VERSION ""

NS_ :

BS_:

BU_: TIS_SN2000

BO_ 2630877422 TIS_SN2000_CMD: 8 Vector__XXX
 SG_ SN2000_Set_MetaData_Time m1114112 : 32|32@1+ (1,0) [0|0] "ms"  TIS_SN2000
 SG_ SN2000_Set_Averages m1048576 : 32|16@1+ (1,0) [1|65535] ""  TIS_SN2000
 SG_ SN2000_Send_IDs m917504 : 24|8@1+ (1,0) [0|0] ""  TIS_SN2000
 SG_ SN2000_Sweep_Stepsize m851968 : 32|32@1- (1,0) [0|0] ""  TIS_SN2000
 SG_ SN2000_Sweep_Stop m786432 : 32|32@1- (1,0) [10000|1000000] ""  TIS_SN2000
 SG_ SN2000_Sweep_Start m720896 : 32|32@1- (1,0) [10000|1000000] ""  TIS_SN2000
 SG_ SN2000_Factory_Reset m589824 : 24|8@1+ (1,0) [0|0] ""  TIS_SN2000
 SG_ SN2000_Set_Gain_F3 m524802 : 32|16@1+ (1,0) [0|2047] ""  TIS_SN2000
 SG_ SN2000_Set_Gain_F2 m524546 : 32|16@1+ (1,0) [0|2047] ""  TIS_SN2000
 SG_ SN2000_Set_Gain_F1 m524290 : 32|16@1+ (1,0) [0|2047] ""  TIS_SN2000
 SG_ SN2000_Set_AdditionalData_Time m393216 : 32|32@1+ (1,0) [0|0] "ms"  TIS_SN2000
 SG_ SN2000_Set_Sample_Time m327680 : 32|32@1+ (1,0) [0|0] "ms"  TIS_SN2000
 SG_ SN2000_Set_Baud m262144 : 24|8@1+ (1,0) [0|5] ""  TIS_SN2000
 SG_ SN2000_Set_F3 m131584 : 32|32@1- (1,0) [10000|1000000] "Hz"  TIS_SN2000
 SG_ SN2000_Set_F2 m131328 : 32|32@1- (1,0) [10000|1000000] "Hz"  TIS_SN2000
 SG_ SN2000_Set_F1 m131072 : 32|32@1- (1,0) [10000|1000000] "Hz"  TIS_SN2000
 SG_ SN2000_Save_Settings m65536 : 24|8@1+ (1,0) [0|0] ""  TIS_SN2000
 SG_ SN2000_Go_Idle m0 : 24|8@1+ (1,0) [0|0] ""  TIS_SN2000
 SG_ SN2000_CMD M : 0|24@1+ (1,0) [0|0] ""  TIS_SN2000

BO_ 2630887150 TIS_SN2000_ERef_Sweep_Amp: 8 TIS_SN2000
 SG_ SN2000_ERef_Sweep_Amp_F : 0|32@1- (1,0) [0|1000000000] "Hz" Vector__XXX
 SG_ SN2000_ERef_Sweep_Amp : 32|32@1- (1,0) [-65535|65535] "" Vector__XXX

BO_ 2630887406 TIS_SN2000_ERef_Sweep_Ph: 8 TIS_SN2000
 SG_ SN2000_ERef_Sweep_Ph_F : 0|32@1- (1,0) [0|1000000000] "Hz" Vector__XXX
 SG_ SN2000_ERef_Sweep_Ph : 32|32@1- (57.295779513,0) [-65535|65535] "" Vector__XXX

BO_ 2630887662 TIS_SN2000_EMicro_Sweep_Amp: 8 TIS_SN2000
 SG_ SN2000_EMicro_Sweep_Amp_F : 0|32@1- (1,0) [0|1000000000] "Hz" Vector__XXX
 SG_ SN2000_EMicro_Sweep_Amp : 32|32@1- (1,0) [-65535|65535] "" Vector__XXX

BO_ 2630887918 TIS_SN2000_EMicro_Sweep_Ph: 8 TIS_SN2000
 SG_ SN2000_EMicro_Sweep_Ph_F : 0|32@1- (1,0) [0|1000000000] "Hz" Vector__XXX
 SG_ SN2000_EMicro_Sweep_Ph : 32|32@1- (57.295779513,0) [-65535|65535] "" Vector__XXX

BO_ 2630888174 TIS_SN2000_E1_Sweep_Amp: 8 TIS_SN2000
 SG_ SN2000_E1_Sweep_Amp_F : 0|32@1- (1,0) [0|1000000000] "Hz" Vector__XXX
 SG_ SN2000_E1_Sweep_Amp : 32|32@1- (1,0) [-65535|65535] "" Vector__XXX

BO_ 2630888430 TIS_SN2000_E1_Sweep_Ph: 8 TIS_SN2000
 SG_ SN2000_E1_Sweep_Ph_F : 0|32@1- (1,0) [0|1000000000] "Hz" Vector__XXX
 SG_ SN2000_E1_Sweep_Ph : 32|32@1- (57.295779513,0) [-65535|65535] "" Vector__XXX

BO_ 2630888686 TIS_SN2000_E2_Sweep_Amp: 8 TIS_SN2000
 SG_ SN2000_E2_Sweep_Amp_F : 0|32@1- (1,0) [0|1000000000] "Hz" Vector__XXX
 SG_ SN2000_E2_Sweep_Amp : 32|32@1- (1,0) [-65535|65535] "" Vector__XXX

BO_ 2630888942 TIS_SN2000_E2_Sweep_Ph: 8 TIS_SN2000
 SG_ SN2000_E2_Sweep_Ph_F : 0|32@1- (1,0) [0|1000000000] "Hz" Vector__XXX
 SG_ SN2000_E2_Sweep_Ph : 32|32@1- (57.295779513,0) [-65535|65535] "" Vector__XXX

BO_ 2630889198 TIS_SN2000_E3_Sweep_Amp: 8 TIS_SN2000
 SG_ SN2000_E3_Sweep_Amp_F : 0|32@1- (1,0) [0|1000000000] "Hz" Vector__XXX
 SG_ SN2000_E3_Sweep_Amp : 32|32@1- (1,0) [-65535|65535] "" Vector__XXX

BO_ 2630889454 TIS_SN2000_E3_Sweep_Ph: 8 TIS_SN2000
 SG_ SN2000_E3_Sweep_Ph_F : 0|32@1- (1,0) [0|1000000000] "Hz" Vector__XXX
 SG_ SN2000_E3_Sweep_Ph : 32|32@1- (57.295779513,0) [-65535|65535] "" Vector__XXX

BO_ 2630889710 TIS_SN2000_EA_Sweep_Amp: 8 TIS_SN2000
 SG_ SN2000_EA_Sweep_Amp_F : 0|32@1- (1,0) [0|1000000000] "Hz" Vector__XXX
 SG_ SN2000_EA_Sweep_Amp : 32|32@1- (1,0) [-65535|65535] "" Vector__XXX

BO_ 2630889966 TIS_SN2000_EA_Sweep_Ph: 8 TIS_SN2000
 SG_ SN2000_EA_Sweep_Ph_F : 0|32@1- (1,0) [0|1000000000] "Hz" Vector__XXX
 SG_ SN2000_EA_Sweep_Ph : 32|32@1- (57.295779513,0) [-65535|65535] "" Vector__XXX

BO_ 2630877678 TIS_SN2000_ID: 4 TIS_SN2000
 SG_ SN2000_ID : 0|16@1+ (1,0) [0|65535] "" Vector__XXX

BO_ 2630877934 TIS_SN2000_Error: 1 TIS_SN2000
 SG_ SN2000_Error : 0|8@1+ (1,0) [0|255] "" Vector__XXX

BO_ 2630878190 TIS_SN2000_UID_Low: 8 TIS_SN2000
 SG_ SN2000_UID_Low : 0|64@1+ (1,0) [0|0] "" Vector__XXX

BO_ 2630878446 TIS_SN2000_UID_High: 4 TIS_SN2000
 SG_ SN2000_UID_High : 0|32@1+ (1,0) [0|0] "" Vector__XXX

BO_ 2630878702 TIS_SN2000_Temp_1_2: 8 TIS_SN2000
 SG_ SN2000_T1 : 0|32@1- (1,0) [-100|200] "C" Vector__XXX
 SG_ SN2000_T2 : 32|32@1- (1,0) [-100|200] "C" Vector__XXX

BO_ 2630878958 TIS_SN2000_Temp_3_4: 8 TIS_SN2000
 SG_ SN2000_T3 : 0|32@1- (1,0) [-100|200] "C" Vector__XXX
 SG_ SN2000_T4 : 32|32@1- (1,0) [-100|200] "C" Vector__XXX

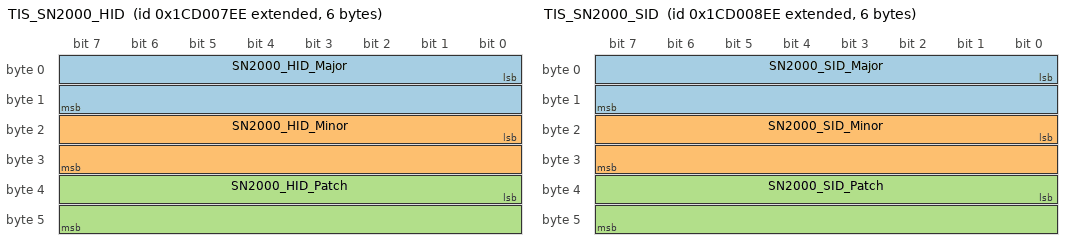
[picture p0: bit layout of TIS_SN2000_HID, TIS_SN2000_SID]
BO_ 2630879214 TIS_SN2000_HID: 6 TIS_SN2000
 SG_ SN2000_HID_Major : 0|16@1+ (1,0) [0|0] "" Vector__XXX
 SG_ SN2000_HID_Minor : 16|16@1+ (1,0) [0|0] "" Vector__XXX
 SG_ SN2000_HID_Patch : 32|16@1+ (1,0) [0|0] "" Vector__XXX

BO_ 2630879470 TIS_SN2000_SID: 6 TIS_SN2000
 SG_ SN2000_SID_Major : 0|16@1+ (1,0) [0|0] "" Vector__XXX
 SG_ SN2000_SID_Minor : 16|16@1+ (1,0) [0|0] "" Vector__XXX
 SG_ SN2000_SID_Patch : 32|16@1+ (1,0) [0|0] "" Vector__XXX

BO_ 2630879726 TIS_SN2000_Systick: 4 TIS_SN2000
 SG_ SN2000_Systick : 0|32@1+ (1,0) [0|0] "" Vector__XXX

BO_ 2630879982 TIS_SN2000_Vbat: 4 TIS_SN2000
 SG_ SN2000_Vbat : 0|32@1- (1,0) [-100|200] "V" Vector__XXX

BO_ 2630880238 TIS_SN2000_Averages: 2 TIS_SN2000
 SG_ SN2000_Averages : 0|16@1+ (1,0) [0|0] "" Vector__XXX

BO_ 2630890222 TIS_SN2000_ERef_F1: 8 TIS_SN2000
 SG_ SN2000_ERef_F1_Amp : 0|32@1- (1,0) [-65535|65535] "" Vector__XXX
 SG_ SN2000_ERef_F1_Ph : 32|32@1- (57.295779513,0) [-65535|65535] "" Vector__XXX

BO_ 2630890478 TIS_SN2000_ERef_F1_Debug: 8 TIS_SN2000
 SG_ SN2000_ERef_F1_Debug : 0|64@1+ (1,0) [0|0] "" Vector__XXX

BO_ 2630890734 TIS_SN2000_EMicro_F1: 8 TIS_SN2000
 SG_ SN2000_EMicro_F1_Amp : 0|32@1- (1,0) [-65535|65535] "" Vector__XXX
 SG_ SN2000_EMicro_F1_Ph : 32|32@1- (57.295779513,0) [-65535|65535] "" Vector__XXX

BO_ 2630890990 TIS_SN2000_EMicro_F1_Debug: 8 TIS_SN2000
 SG_ SN2000_EMicro_F1_Debug : 0|64@1+ (1,0) [0|0] "" Vector__XXX

BO_ 2630891246 TIS_SN2000_E1_F1: 8 TIS_SN2000
 SG_ SN2000_E1_F1_Amp : 0|32@1- (1,0) [-65535|65535] "" Vector__XXX
 SG_ SN2000_E1_F1_Ph : 32|32@1- (57.295779513,0) [-65535|65535] "" Vector__XXX

BO_ 2630891502 TIS_SN2000_E1_F1_Debug: 8 TIS_SN2000
 SG_ SN2000_E1_F1_Debug : 0|64@1+ (1,0) [0|0] "" Vector__XXX

BO_ 2630891758 TIS_SN2000_E2_F1: 8 TIS_SN2000
 SG_ SN2000_E2_F1_Amp : 0|32@1- (1,0) [-65535|65535] "" Vector__XXX
 SG_ SN2000_E2_F1_Ph : 32|32@1- (57.295779513,0) [-65535|65535] "" Vector__XXX

BO_ 2630892014 TIS_SN2000_E2_F1_Debug: 8 TIS_SN2000
 SG_ SN2000_E2_F1_Debug : 0|64@1+ (1,0) [0|0] "" Vector__XXX

BO_ 2630892270 TIS_SN2000_E3_F1: 8 TIS_SN2000
 SG_ SN2000_E3_F1_Amp : 0|32@1- (1,0) [-65535|65535] "" Vector__XXX
 SG_ SN2000_E3_F1_Ph : 32|32@1- (57.295779513,0) [-65535|65535] "" Vector__XXX

BO_ 2630892526 TIS_SN2000_E3_F1_Debug: 8 TIS_SN2000
 SG_ SN2000_E3_F1_Debug : 0|64@1+ (1,0) [0|0] "" Vector__XXX

BO_ 2630892782 TIS_SN2000_EA_F1: 8 TIS_SN2000
 SG_ SN2000_EA_F1_Amp : 0|32@1- (1,0) [-65535|65535] "" Vector__XXX
 SG_ SN2000_EA_F1_Ph : 32|32@1- (57.295779513,0) [-65535|65535] "" Vector__XXX

BO_ 2630893038 TIS_SN2000_EA_F1_Debug: 8 TIS_SN2000
 SG_ SN2000_EA_F1_Debug : 0|64@1+ (1,0) [0|0] "" Vector__XXX

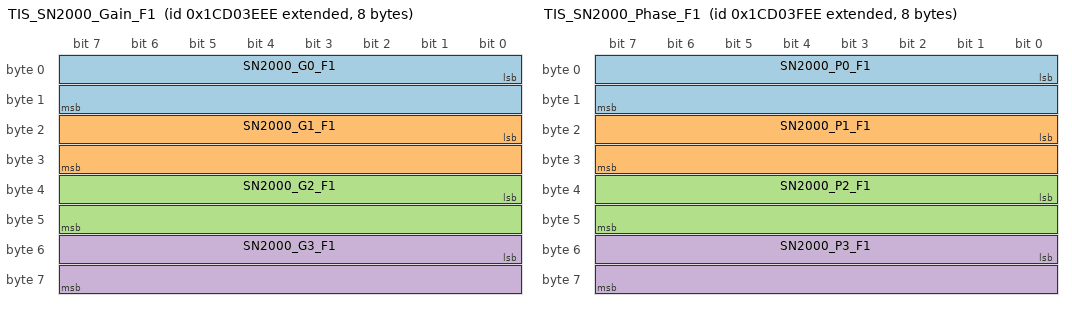
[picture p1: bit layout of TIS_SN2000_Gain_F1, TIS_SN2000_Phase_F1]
BO_ 2630893294 TIS_SN2000_Gain_F1: 8 TIS_SN2000
 SG_ SN2000_G0_F1 : 0|16@1- (1,0) [0|0] "" Vector__XXX
 SG_ SN2000_G1_F1 : 16|16@1- (1,0) [0|0] "" Vector__XXX
 SG_ SN2000_G2_F1 : 32|16@1- (1,0) [0|0] "" Vector__XXX
 SG_ SN2000_G3_F1 : 48|16@1- (1,0) [0|0] "" Vector__XXX

BO_ 2630893550 TIS_SN2000_Phase_F1: 8 TIS_SN2000
 SG_ SN2000_P0_F1 : 0|16@1+ (1,0) [0|0] "" Vector__XXX
 SG_ SN2000_P1_F1 : 16|16@1+ (1,0) [0|0] "" Vector__XXX
 SG_ SN2000_P2_F1 : 32|16@1+ (1,0) [0|0] "" Vector__XXX
 SG_ SN2000_P3_F1 : 48|16@1+ (1,0) [0|0] "" Vector__XXX

BO_ 2630893806 TIS_SN2000_F1: 8 TIS_SN2000
 SG_ SN2000_F1 : 32|32@1- (1,0) [0|1000000000] "Hz" Vector__XXX

BO_ 2630894062 TIS_SN2000_ERef_F2: 8 TIS_SN2000
 SG_ SN2000_ERef_F2_Amp : 0|32@1- (1,0) [-65535|65535] "" Vector__XXX
 SG_ SN2000_ERef_F2_Ph : 32|32@1- (57.295779513,0) [-65535|65535] "" Vector__XXX

BO_ 2630894318 TIS_SN2000_ERef_F2_Debug: 8 TIS_SN2000
 SG_ SN2000_ERef_F2_Debug : 0|64@1+ (1,0) [0|0] "" Vector__XXX

BO_ 2630894574 TIS_SN2000_EMicro_F2: 8 TIS_SN2000
 SG_ SN2000_EMicro_F2_Amp : 0|32@1- (1,0) [-65535|65535] "" Vector__XXX
 SG_ SN2000_EMicro_F2_Ph : 32|32@1- (57.295779513,0) [-65535|65535] "" Vector__XXX

BO_ 2630894830 TIS_SN2000_EMicro_F2_Debug: 8 TIS_SN2000
 SG_ SN2000_EMicro_F2_Debug : 0|64@1+ (1,0) [0|0] "" Vector__XXX

BO_ 2630895086 TIS_SN2000_E1_F2: 8 TIS_SN2000
 SG_ SN2000_E1_F2_Amp : 0|32@1- (1,0) [-65535|65535] "" Vector__XXX
 SG_ SN2000_E1_F2_Ph : 32|32@1- (57.295779513,0) [-65535|65535] "" Vector__XXX

BO_ 2630895342 TIS_SN2000_E1_F2_Debug: 8 TIS_SN2000
 SG_ SN2000_E1_F2_Debug : 0|64@1+ (1,0) [0|0] "" Vector__XXX

BO_ 2630895598 TIS_SN2000_E2_F2: 8 TIS_SN2000
 SG_ SN2000_E2_F2_Amp : 0|32@1- (1,0) [-65535|65535] "" Vector__XXX
 SG_ SN2000_E2_F2_Ph : 32|32@1- (57.295779513,0) [-65535|65535] "" Vector__XXX

BO_ 2630895854 TIS_SN2000_E2_F2_Debug: 8 TIS_SN2000
 SG_ SN2000_E2_F2_Debug : 0|64@1+ (1,0) [0|0] "" Vector__XXX

BO_ 2630896110 TIS_SN2000_E3_F2: 8 TIS_SN2000
 SG_ SN2000_E3_F2_Amp : 0|32@1- (1,0) [-65535|65535] "" Vector__XXX
 SG_ SN2000_E3_F2_Ph : 32|32@1- (57.295779513,0) [-65535|65535] "" Vector__XXX

BO_ 2630896366 TIS_SN2000_E3_F2_Debug: 8 TIS_SN2000
 SG_ SN2000_E3_F2_Debug : 0|64@1+ (1,0) [0|0] "" Vector__XXX

BO_ 2630896622 TIS_SN2000_EA_F2: 8 TIS_SN2000
 SG_ SN2000_EA_F2_Amp : 0|32@1- (1,0) [-65535|65535] "" Vector__XXX
 SG_ SN2000_EA_F2_Ph : 32|32@1- (57.295779513,0) [-65535|65535] "" Vector__XXX

BO_ 2630896878 TIS_SN2000_EA_F2_Debug: 8 TIS_SN2000
 SG_ SN2000_EA_F2_Debug : 0|64@1+ (1,0) [0|0] "" Vector__XXX

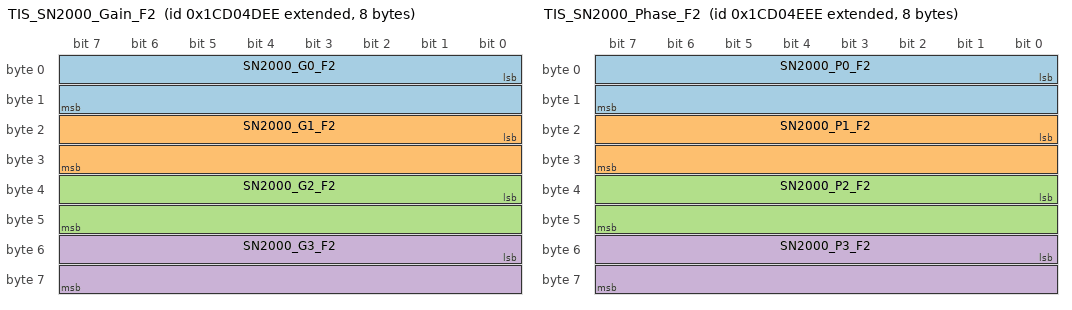
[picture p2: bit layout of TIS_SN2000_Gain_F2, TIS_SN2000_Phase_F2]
BO_ 2630897134 TIS_SN2000_Gain_F2: 8 TIS_SN2000
 SG_ SN2000_G0_F2 : 0|16@1- (1,0) [0|0] "" Vector__XXX
 SG_ SN2000_G1_F2 : 16|16@1- (1,0) [0|0] "" Vector__XXX
 SG_ SN2000_G2_F2 : 32|16@1- (1,0) [0|0] "" Vector__XXX
 SG_ SN2000_G3_F2 : 48|16@1- (1,0) [0|0] "" Vector__XXX

BO_ 2630897390 TIS_SN2000_Phase_F2: 8 TIS_SN2000
 SG_ SN2000_P0_F2 : 0|16@1+ (1,0) [0|0] "" Vector__XXX
 SG_ SN2000_P1_F2 : 16|16@1+ (1,0) [0|0] "" Vector__XXX
 SG_ SN2000_P2_F2 : 32|16@1+ (1,0) [0|0] "" Vector__XXX
 SG_ SN2000_P3_F2 : 48|16@1+ (1,0) [0|0] "" Vector__XXX

BO_ 2630897646 TIS_SN2000_F2: 8 TIS_SN2000
 SG_ SN2000_F2 : 32|32@1- (1,0) [0|1000000000] "Hz" Vector__XXX

BO_ 2630897902 TIS_SN2000_ERef_F3: 8 TIS_SN2000
 SG_ SN2000_ERef_F3_Amp : 0|32@1- (1,0) [-65535|65535] "" Vector__XXX
 SG_ SN2000_ERef_F3_Ph : 32|32@1- (57.295779513,0) [-65535|65535] "" Vector__XXX

BO_ 2630898158 TIS_SN2000_ERef_F3_Debug: 8 TIS_SN2000
 SG_ SN2000_ERef_F3_Debug : 0|64@1+ (1,0) [0|0] "" Vector__XXX

BO_ 2630898414 TIS_SN2000_EMicro_F3: 8 TIS_SN2000
 SG_ SN2000_EMicro_F3_Amp : 0|32@1- (1,0) [-65535|65535] "" Vector__XXX
 SG_ SN2000_EMicro_F3_Ph : 32|32@1- (57.295779513,0) [-65535|65535] "" Vector__XXX

BO_ 2630898670 TIS_SN2000_EMicro_F3_Debug: 8 TIS_SN2000
 SG_ SN2000_EMicro_F3_Debug : 0|64@1+ (1,0) [0|0] "" Vector__XXX

BO_ 2630898926 TIS_SN2000_E1_F3: 8 TIS_SN2000
 SG_ SN2000_E1_F3_Amp : 0|32@1- (1,0) [-65535|65535] "" Vector__XXX
 SG_ SN2000_E1_F3_Ph : 32|32@1- (57.295779513,0) [-65535|65535] "" Vector__XXX

BO_ 2630899182 TIS_SN2000_E1_F3_Debug: 8 TIS_SN2000
 SG_ SN2000_E1_F3_Debug : 0|64@1+ (1,0) [0|0] "" Vector__XXX

BO_ 2630899438 TIS_SN2000_E2_F3: 8 TIS_SN2000
 SG_ SN2000_E2_F3_Amp : 0|32@1- (1,0) [-65535|65535] "" Vector__XXX
 SG_ SN2000_E2_F3_Ph : 32|32@1- (57.295779513,0) [-65535|65535] "" Vector__XXX

BO_ 2630899694 TIS_SN2000_E2_F3_Debug: 8 TIS_SN2000
 SG_ SN2000_E2_F3_Debug : 0|64@1+ (1,0) [0|0] "" Vector__XXX

BO_ 2630899950 TIS_SN2000_E3_F3: 8 TIS_SN2000
 SG_ SN2000_E3_F3_Amp : 0|32@1- (1,0) [-65535|65535] "" Vector__XXX
 SG_ SN2000_E3_F3_Ph : 32|32@1- (57.295779513,0) [-65535|65535] "" Vector__XXX

BO_ 2630900206 TIS_SN2000_E3_F3_Debug: 8 TIS_SN2000
 SG_ SN2000_E3_F3_Debug : 0|64@1+ (1,0) [0|0] "" Vector__XXX

BO_ 2630900462 TIS_SN2000_EA_F3: 8 TIS_SN2000
 SG_ SN2000_EA_F3_Amp : 0|32@1- (1,0) [-65535|65535] "" Vector__XXX
 SG_ SN2000_EA_F3_Ph : 32|32@1- (57.295779513,0) [-65535|65535] "" Vector__XXX

BO_ 2630900718 TIS_SN2000_EA_F3_Debug: 8 TIS_SN2000
 SG_ SN2000_EA_F3_Debug : 0|64@1+ (1,0) [0|0] "" Vector__XXX

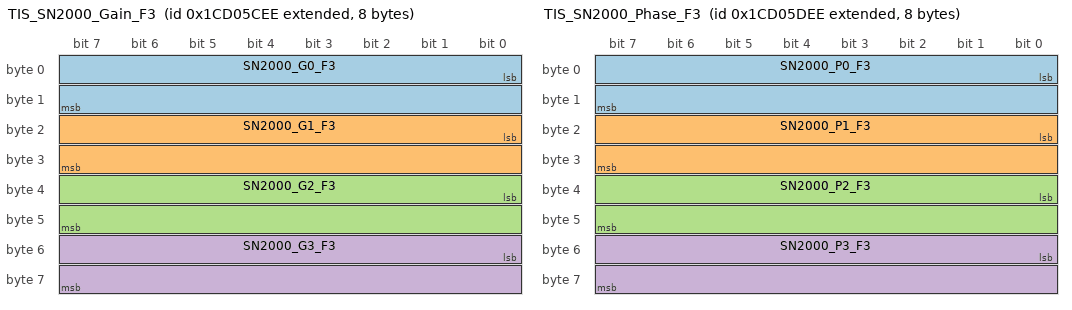
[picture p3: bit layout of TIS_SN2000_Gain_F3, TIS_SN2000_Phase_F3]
BO_ 2630900974 TIS_SN2000_Gain_F3: 8 TIS_SN2000
 SG_ SN2000_G0_F3 : 0|16@1- (1,0) [0|0] "" Vector__XXX
 SG_ SN2000_G1_F3 : 16|16@1- (1,0) [0|0] "" Vector__XXX
 SG_ SN2000_G2_F3 : 32|16@1- (1,0) [0|0] "" Vector__XXX
 SG_ SN2000_G3_F3 : 48|16@1- (1,0) [0|0] "" Vector__XXX

BO_ 2630901230 TIS_SN2000_Phase_F3: 8 TIS_SN2000
 SG_ SN2000_P0_F3 : 0|16@1+ (1,0) [0|0] "" Vector__XXX
 SG_ SN2000_P1_F3 : 16|16@1+ (1,0) [0|0] "" Vector__XXX
 SG_ SN2000_P2_F3 : 32|16@1+ (1,0) [0|0] "" Vector__XXX
 SG_ SN2000_P3_F3 : 48|16@1+ (1,0) [0|0] "" Vector__XXX

BO_ 2630901486 TIS_SN2000_F3: 8 TIS_SN2000
 SG_ SN2000_F3 : 32|32@1- (1,0) [0|1000000000] "Hz" Vector__XXX

VAL_ 2630877422 SN2000_Set_Baud 0 "100 kBaud" 1 "125 kBaud" 2 "200 kBaud" 3 "250 kBaud" 4 "500 kBaud" 5 "1000 kBaud" ;
SIG_VALTYPE_ 2630877422 SN2000_Sweep_Stepsize : 1;
SIG_VALTYPE_ 2630877422 SN2000_Sweep_Stop : 1;
SIG_VALTYPE_ 2630877422 SN2000_Sweep_Start : 1;
SIG_VALTYPE_ 2630887150 SN2000_ERef_Sweep_Amp_F : 1;
SIG_VALTYPE_ 2630887150 SN2000_ERef_Sweep_Amp : 1;
SIG_VALTYPE_ 2630887406 SN2000_ERef_Sweep_Ph_F : 1;
SIG_VALTYPE_ 2630887406 SN2000_ERef_Sweep_Ph : 1;
SIG_VALTYPE_ 2630887662 SN2000_EMicro_Sweep_Amp_F : 1;
SIG_VALTYPE_ 2630887662 SN2000_EMicro_Sweep_Amp : 1;
SIG_VALTYPE_ 2630887918 SN2000_EMicro_Sweep_Ph_F : 1;
SIG_VALTYPE_ 2630887918 SN2000_EMicro_Sweep_Ph : 1;
SIG_VALTYPE_ 2630888174 SN2000_E1_Sweep_Amp_F : 1;
SIG_VALTYPE_ 2630888174 SN2000_E1_Sweep_Amp : 1;
SIG_VALTYPE_ 2630888430 SN2000_E1_Sweep_Ph_F : 1;
SIG_VALTYPE_ 2630888430 SN2000_E1_Sweep_Ph : 1;
SIG_VALTYPE_ 2630888686 SN2000_E2_Sweep_Amp_F : 1;
SIG_VALTYPE_ 2630888686 SN2000_E2_Sweep_Amp : 1;
SIG_VALTYPE_ 2630888942 SN2000_E2_Sweep_Ph_F : 1;
SIG_VALTYPE_ 2630888942 SN2000_E2_Sweep_Ph : 1;
SIG_VALTYPE_ 2630889198 SN2000_E3_Sweep_Amp_F : 1;
SIG_VALTYPE_ 2630889198 SN2000_E3_Sweep_Amp : 1;
SIG_VALTYPE_ 2630889454 SN2000_E3_Sweep_Ph_F : 1;
SIG_VALTYPE_ 2630889454 SN2000_E3_Sweep_Ph : 1;
SIG_VALTYPE_ 2630889710 SN2000_EA_Sweep_Amp_F : 1;
SIG_VALTYPE_ 2630889710 SN2000_EA_Sweep_Amp : 1;
SIG_VALTYPE_ 2630889966 SN2000_EA_Sweep_Ph_F : 1;
SIG_VALTYPE_ 2630889966 SN2000_EA_Sweep_Ph : 1;
SIG_VALTYPE_ 2630878702 SN2000_T1 : 1;
SIG_VALTYPE_ 2630878702 SN2000_T2 : 1;
SIG_VALTYPE_ 2630878958 SN2000_T3 : 1;
SIG_VALTYPE_ 2630878958 SN2000_T4 : 1;
SIG_VALTYPE_ 2630879982 SN2000_Vbat : 1;
SIG_VALTYPE_ 2630890222 SN2000_ERef_F1_Amp : 1;
SIG_VALTYPE_ 2630890222 SN2000_ERef_F1_Ph : 1;
SIG_VALTYPE_ 2630890734 SN2000_EMicro_F1_Amp : 1;
SIG_VALTYPE_ 2630890734 SN2000_EMicro_F1_Ph : 1;
SIG_VALTYPE_ 2630891246 SN2000_E1_F1_Amp : 1;
SIG_VALTYPE_ 2630891246 SN2000_E1_F1_Ph : 1;
SIG_VALTYPE_ 2630891758 SN2000_E2_F1_Amp : 1;
SIG_VALTYPE_ 2630891758 SN2000_E2_F1_Ph : 1;
SIG_VALTYPE_ 2630892270 SN2000_E3_F1_Amp : 1;
SIG_VALTYPE_ 2630892270 SN2000_E3_F1_Ph : 1;
SIG_VALTYPE_ 2630892782 SN2000_EA_F1_Amp : 1;
SIG_VALTYPE_ 2630892782 SN2000_EA_F1_Ph : 1;
SIG_VALTYPE_ 2630893806 SN2000_F1 : 1;
SIG_VALTYPE_ 2630894062 SN2000_ERef_F2_Amp : 1;
SIG_VALTYPE_ 2630894062 SN2000_ERef_F2_Ph : 1;
SIG_VALTYPE_ 2630894574 SN2000_EMicro_F2_Amp : 1;
SIG_VALTYPE_ 2630894574 SN2000_EMicro_F2_Ph : 1;
SIG_VALTYPE_ 2630895086 SN2000_E1_F2_Amp : 1;
SIG_VALTYPE_ 2630895086 SN2000_E1_F2_Ph : 1;
SIG_VALTYPE_ 2630895598 SN2000_E2_F2_Amp : 1;
SIG_VALTYPE_ 2630895598 SN2000_E2_F2_Ph : 1;
SIG_VALTYPE_ 2630896110 SN2000_E3_F2_Amp : 1;
SIG_VALTYPE_ 2630896110 SN2000_E3_F2_Ph : 1;
SIG_VALTYPE_ 2630896622 SN2000_EA_F2_Amp : 1;
SIG_VALTYPE_ 2630896622 SN2000_EA_F2_Ph : 1;
SIG_VALTYPE_ 2630897646 SN2000_F2 : 1;
SIG_VALTYPE_ 2630897902 SN2000_ERef_F3_Amp : 1;
SIG_VALTYPE_ 2630897902 SN2000_ERef_F3_Ph : 1;
SIG_VALTYPE_ 2630898414 SN2000_EMicro_F3_Amp : 1;
SIG_VALTYPE_ 2630898414 SN2000_EMicro_F3_Ph : 1;
SIG_VALTYPE_ 2630898926 SN2000_E1_F3_Amp : 1;
SIG_VALTYPE_ 2630898926 SN2000_E1_F3_Ph : 1;
SIG_VALTYPE_ 2630899438 SN2000_E2_F3_Amp : 1;
SIG_VALTYPE_ 2630899438 SN2000_E2_F3_Ph : 1;
SIG_VALTYPE_ 2630899950 SN2000_E3_F3_Amp : 1;
SIG_VALTYPE_ 2630899950 SN2000_E3_F3_Ph : 1;
SIG_VALTYPE_ 2630900462 SN2000_EA_F3_Amp : 1;
SIG_VALTYPE_ 2630900462 SN2000_EA_F3_Ph : 1;
SIG_VALTYPE_ 2630901486 SN2000_F3 : 1;
